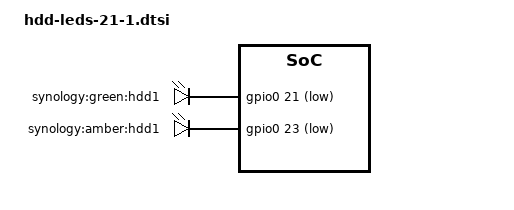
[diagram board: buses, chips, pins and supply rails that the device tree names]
/*
 * Andrew Lunn <andrew@lunn.ch>
 *
 * This file is licensed under the terms of the GNU General Public
 * License version 2.  This program is licensed "as is" without any
 * warranty of any kind, whether express or implied.
 */

/ {
	ocp@f1000000 {
		pinctrl: pinctrl@10000 {

			pmx_led_21: pmx-led-21 {
				marvell,pins = "mpp21";
				marvell,function = "gpio";
			};
			pmx_led_23: pmx-led-23 {
				marvell,pins = "mpp23";
				marvell,function = "gpio";
			};
		};
	};
	gpio-leds {
		compatible = "gpio-leds";
		pinctrl-0 = <&pmx_led_21 &pmx_led_23>;
		pinctrl-names = "default";
		hdd1-green {
			label = "synology:green:hdd1";
			gpios = <&gpio0 21 GPIO_ACTIVE_LOW>;
		};
		hdd1-amber {
			label = "synology:amber:hdd1";
			gpios = <&gpio0 23 GPIO_ACTIVE_LOW>;
		};
	};
};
